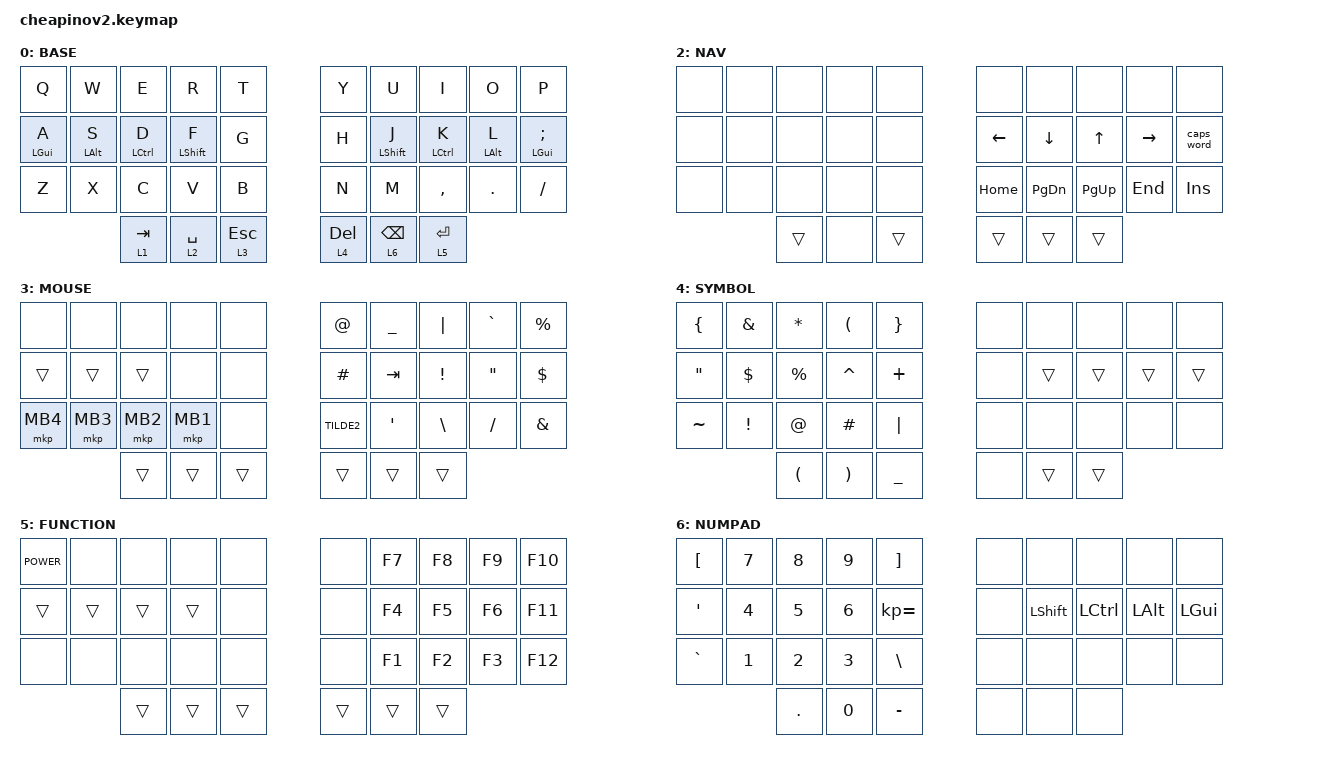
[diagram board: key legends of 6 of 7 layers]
//     ___ _                      _ 
//    / __\ |___  ___  __ _ _ __ (_)_ ___  ____
//   / /  | '_  \/ _ \/ _` | '_ \| | '_  \/ _  \
//  / /___| | | |  __/ (_| | |_) | | | | | (_) |
//  \____/|_| |_|\___|\__,_| .__/|_|_| |_|\___/
//                         |_|

#include <behaviors.dtsi>
#include <dt-bindings/zmk/keys.h>
#include <dt-bindings/zmk/bt.h>
#include <dt-bindings/zmk/mouse.h>

#define BASE 0
#define MEDIA  1
#define SYM  2
#define ADJ  3

&mt {
  quick-tap-ms = <150>;
  global-quick-tap;
  flavor = "tap-preferred";
  tapping-term-ms = <150>;
  require-prior-idle-ms = <150>;
  hold-trigger-on-release;
};

&caps_word {
    continue-list = <UNDERSCORE MINUS BACKSPACE>;
};

/ {
        keymap {
                compatible = "zmk,keymap";
        BASE {
          bindings = <
          &kp Q &kp W &kp E &kp R &kp T &kp Y &kp U &kp I &kp O &kp P
          &mt LEFT_GUI A &mt LEFT_ALT S &mt LEFT_CONTROL D &mt LEFT_SHIFT F &kp G &kp H &mt LEFT_SHIFT J &mt LEFT_CONTROL K &mt LEFT_ALT L &mt LEFT_GUI SEMICOLON
          &kp Z &kp X &kp C &kp V &kp B &kp N &kp M &kp COMMA &kp DOT &kp SLASH
          &lt 1 TAB &lt 2 SPACE &lt 3 ESC &lt 4 DELETE &lt 6 BACKSPACE &lt 5 ENTER
          >;
        };
        MEDIA {
          bindings = <
          &kp C_VOLUME_UP &none &none &none &none &bt BT_CLR_ALL &bt BT_PRV &bt BT_NXT &kp C_POWER 
          &none &none &none &none &kp C_MUTE &none &trans &trans &trans &trans 
          &kp C_VOLUME_DOWN &kp C_NEXT &none &none &kp C_PLAY_PAUSE &none &none &none &none &none 
              &none &trans &trans &none &none &none
          >;
        };
        NAV {
          bindings = <
          &none &none &none &none &none &none &none &none &none &none
          &none &none &none &none &none &kp LEFT &kp DOWN &kp UP &kp RIGHT &caps_word 
          &none &none &none &none &none &kp HOME &kp PG_DN &kp PG_UP &kp END &kp INS
              &trans &none &trans &trans &trans &trans
          >;
        };
        MOUSE {
          bindings = <
          &none &none &none &none &none                 &kp AT &kp UNDERSCORE &kp PIPE &kp GRAVE &kp PERCENT
          &trans &trans &trans &none &none              &kp HASH &kp TAB &kp EXCLAMATION &kp DOUBLE_QUOTES &kp DOLLAR
          &mkp MB4 &mkp MB3 &mkp MB2 &mkp MB1 &none     &kp TILDE2 &kp SINGLE_QUOTE &kp BACKSLASH &kp SLASH &kp AMPERSAND
              &trans &trans &trans &trans &trans &trans
          >;
        };
        SYMBOL {
          bindings = <
          &kp LEFT_BRACE &kp AMPERSAND &kp ASTERISK &kp LEFT_PARENTHESIS &kp RIGHT_BRACE              &none &none &none &none &none 
          &kp DOUBLE_QUOTES &kp DOLLAR &kp PERCENT &kp CARET &kp PLUS                                 &none &trans &trans &trans &trans 
          &kp TILDE &kp EXCL &kp AT &kp HASH &kp PIPE                     &none &none &none &none &none 
					&kp LEFT_PARENTHESIS &kp RIGHT_PARENTHESIS &kp UNDERSCORE &none &trans &trans
          >;
        };
        FUNCTION {
          bindings = <
          &kp C_POWER &none &none &none &none &none &kp F7 &kp F8 &kp F9 &kp F10 
          &trans &trans &trans &trans &none &none &kp F4 &kp F5 &kp F6 &kp F11 
          &none &none &none &none &none &none &kp F1 &kp F2 &kp F3 &kp F12 
              &trans &trans &trans &trans &trans &trans
          >;
        };
        NUMPAD {
          bindings = <
          &kp LEFT_BRACKET &kp N7 &kp N8 &kp N9 &kp RIGHT_BRACKET &none &none &none &none &none
          &kp SINGLE_QUOTE &kp N4 &kp N5 &kp N6 &kp KP_EQUAL &none &kp LEFT_SHIFT &kp LEFT_CONTROL &kp LEFT_ALT &kp LEFT_GUI
          &kp GRAVE &kp N1 &kp N2 &kp N3 &kp BACKSLASH &none &none &none &none &none
             &kp DOT &kp N0 &kp MINUS &none &none &none
          >;
        };
    };
};

// &kp LEFT_BRACKET &kp N7 &kp N8 &kp N9 &kp RIGHT_BRACKET &none &none &none &none &none
// &kp SEMICOLON &kp N4 &kp N5 &kp N6 &kp KP_EQUAL &none &trans &trans &trans &none
// &kp GRAVE &kp N1 &kp N2 &kp N3 &kp BACKSLASH &none &none &none &none &none
// &kp DOT &kp N0 &kp DASH &none &none &none
